# SF32LB55x register map
File version: 1.0
CPU: CM33 r0p1, little endian, MPU, FPU, 3 interrupt priority bits
Registers are 32-bit, read-write, reset 0x0 unless marked. A register's access mark holds for its fields unless they carry their own. Offsets are from the block's base; [hi:lo] are bit positions; {n}, {i} and the like mark numbered series; 'fields as' and 'values as' point back to an identical list.

## PTC1
Base 0x40020000
Same registers: PTC2 0x4005B000
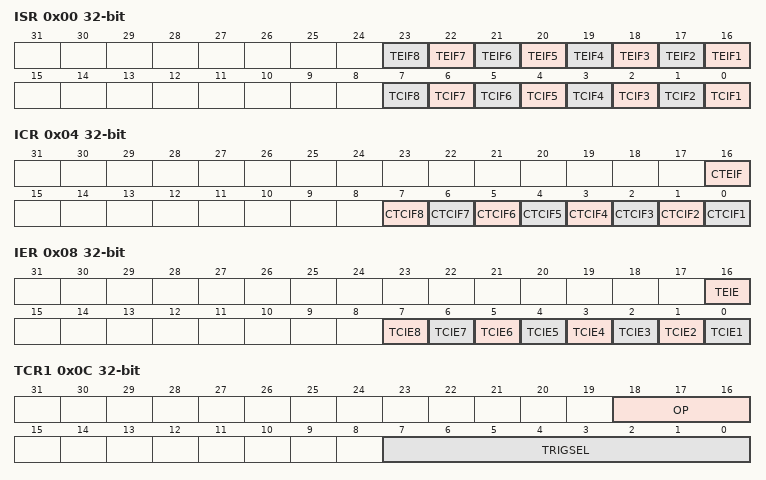
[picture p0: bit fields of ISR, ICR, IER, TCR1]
0x00 ISR — interrupt status register
  [n+15] TEIF{n} (n=1..8) — transfer error flag for task {n}
  [n-1] TCIF{n} (n=1..8) — task complete interrupt flag for task {n}
0x04 ICR — interrupt clear register
  [16] CTEIF — clear transfer error flag
  [n-1] CTCIF{n} (n=1..8) — clear task complete interrupt flag for task {n}
0x08 IER — interrupt enable register
  [16] TEIE — enable transfer error flag
  [n-1] TCIE{n} (n=1..8) — enable task complete interrupt for task {n}
0x0C TCR1 — task 1 control register
  [18:16] OP — task operation 3'b000: direct write data 3'b100: read then XOR with data and write back 3'b101: read then OR with data and write back 3'b110: read then AND with data and write back 3'b111: read then add with data and write back
  [7:0] TRIGSEL — select trigger source 0: task will not be triggered others: task will be triggered by selected source
0x10 TAR1 — task 1 address register
  [31:0] ADDR — peripheral address to access to
0x14 TDR1 — task 1 data register
  [31:0] DATA — data value for task operation
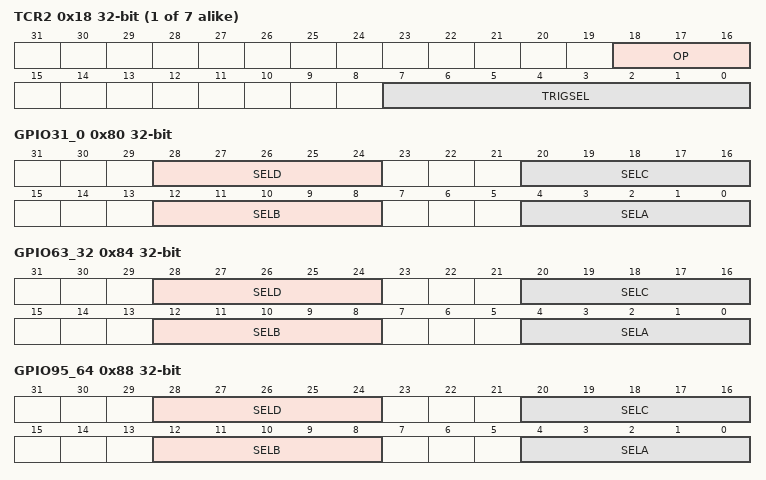
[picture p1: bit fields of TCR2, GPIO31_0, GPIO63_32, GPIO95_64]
{0x0+0xC*i} TCR{i} (i=2..8)
  fields as TCR1
{0x4+0xC*i} TAR{i} (i=2..8)
  [31:0] ADDR — peripheral address to access to
{0x8+0xC*i} TDR{i} (i=2..8)
  [31:0] DATA — data value for task operation
{0x6C+4i} MEM{i} (i=1..4) — temporary memory {i}
  [31:0] DATA — memory to store temporary variables
0x80 GPIO31_0
  [28:24] SELD — select trigger D of GPIO 31~0
  [20:16] SELC — select trigger C of GPIO 31~0
  [12:8] SELB — select trigger B of GPIO 31~0
  [4:0] SELA — select trigger A of GPIO 31~0 0: select GPIO 0 1: select GPIO 1 ...... 31: select GPIO 31
0x84 GPIO63_32
  [28:24] SELD — select trigger D of GPIO 63~32
  [20:16] SELC — select trigger C of GPIO 63~32
  [12:8] SELB — select trigger B of GPIO 63~32
  [4:0] SELA — select trigger A of GPIO 63~32 0: select GPIO 32 1: select GPIO 33 ...... 31: select GPIO 63
0x88 GPIO95_64
  [28:24] SELD — select trigger D of GPIO 95~64
  [20:16] SELC — select trigger C of GPIO 95~64
  [12:8] SELB — select trigger B of GPIO 95~64
  [4:0] SELA — select trigger A of GPIO 95~64 0: select GPIO 64 1: select GPIO 65 ...... 31: select GPIO 95

## HPSYS_AON
Base 0x40030000
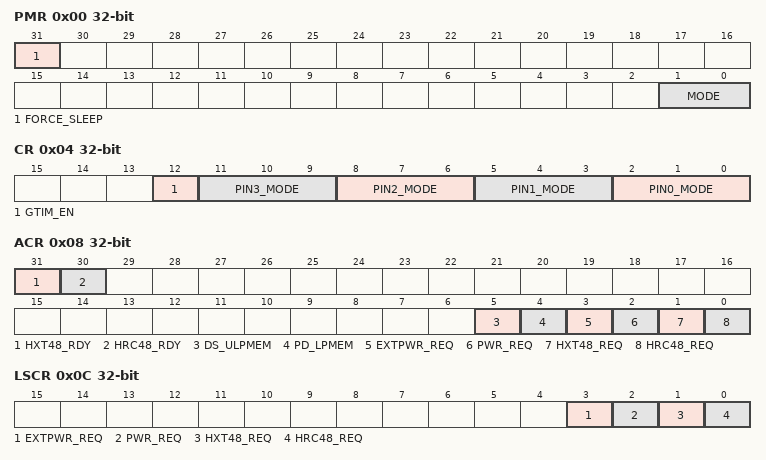
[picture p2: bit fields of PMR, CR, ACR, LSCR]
0x00 PMR — Power Mode Register
  [31] FORCE_SLEEP — force to enter low power mode (for debug only)
  [1:0] MODE — Power Mode: 2'h0 - active/idle; 2'h1 - light sleep; 2'h2 - deep sleep; 2'h3 - standby
0x04 CR — Control Register
  [12] GTIM_EN — Enable global timer
  [11:9] PIN3_MODE — mode for wakeup PIN3 (PA80)
  [8:6] PIN2_MODE — mode for wakeup PIN2 (PA79)
  [5:3] PIN1_MODE — mode for wakeup PIN1 (PA78)
  [2:0] PIN0_MODE — mode for wakeup PIN0 (PA77) 0 - high level, 1 - low level, 2 - pos edge, 3 - neg edge, 4/5/6/7: pos or neg edge
0x08 ACR — Active Mode Control register
  [31] HXT48_RDY — Indicate hxt48 is ready
  [30] HRC48_RDY — Indicate hrc48 is ready
  [5] DS_ULPMEM — for debug only
  [4] PD_LPMEM — for debug only
  [3] EXTPWR_REQ — Request power for LPSYS during Active mode
  [2] PWR_REQ — Request power for HPSYS during Active mode
  [1] HXT48_REQ — Request hxt48 in active mode
  [0] HRC48_REQ — Request hrc48 in active mode
0x0C LSCR — Light Sleep Ctrl Register
  [3] EXTPWR_REQ — Request power for LPSYS during Light Sleep mode
  [2] PWR_REQ — Request power for HPSYS during Light Sleep mode
  [1] HXT48_REQ — Request hxt48 in Light Sleep mode
  [0] HRC48_REQ — Request hrc48 in Light Sleep mode
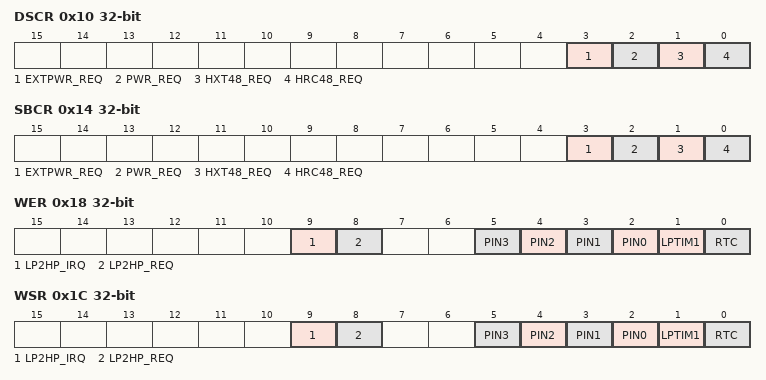
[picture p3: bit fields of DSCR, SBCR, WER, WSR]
0x10 DSCR — Deep Sleep Ctrl Register
  [3] EXTPWR_REQ — Request power for LPSYS during Deep Sleep mode
  [2] PWR_REQ — Request power for HPSYS during Deep Sleep mode
  [1] HXT48_REQ — Request hxt48 in Deep Sleep mode
  [0] HRC48_REQ — Request hrc48 in Deep Sleep mode
0x14 SBCR — Standby Mode Ctrl Register
  [3] EXTPWR_REQ — Request power for LPSYS during Standby mode
  [2] PWR_REQ — Request power for HPSYS during Standby mode
  [1] HXT48_REQ — Request hxt48 in Standby mode
  [0] HRC48_REQ — Request hrc48 in Standby mode
0x18 WER — Wakeup Enable register
  [9] LP2HP_IRQ — Set 1 to enable MAILBOX2 as wakeup source
  [8] LP2HP_REQ — Set 1 to enable LPSYS request as wakeup source
  [n+2] PIN{n} (n=0..3) — Set 1 to enable PA{n+77} as wakeup source
  [1] LPTIM1 — Set 1 to enable LPTIM1 as wakeup source
  [0] RTC — Set 1 to enable RTC as wakeup source
0x1C WSR — Wakeup Status register
  [9] LP2HP_IRQ — Indicates the wakeup status from MAILBOX2. Note: the status is masked by WER
  [8] LP2HP_REQ — Indicates the wakeup status from LPSYS request. Note: the status is masked by WER
  [n+2] PIN{n} (n=0..3) — Indicates the wakeup status from PA{n+77} request. Note: the status is masked by WER
  [1] LPTIM1 — Indicates the wakeup status from LPTIM1. Note: the status is masked by WER
  [0] RTC — Indicates the wakeup status from RTC. Note: the status is masked by WER
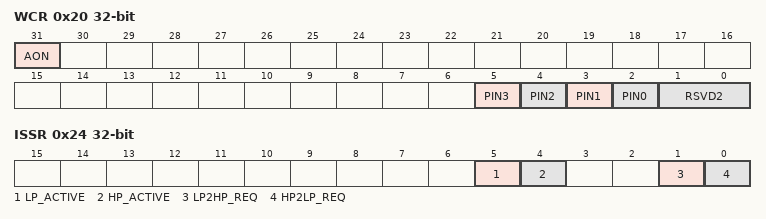
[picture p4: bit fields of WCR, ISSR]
0x20 WCR — Wakeup Clear register
  [31] AON — Write 1 to clear the AON wakeup IRQ status
  [n+2] PIN{n} (n=0..3) — Write 1 to clear the PA{n+77} wakeup source. Only valid if PIN wakeup is configured as edge trigger
  [1:0] RSVD2 — Note: for LPTIM and RTC, clear the wakeup status directly in the orignal module
0x24 ISSR — Inter System Wakeup Register
  [5] LP_ACTIVE — read 1 indicates LPSYS is active
  [4] HP_ACTIVE — write 1 to indicates HPSYS is active
  [1] LP2HP_REQ — indicate LPSYS request exists
  [0] HP2LP_REQ — write 1 to request LPSYS to stay in active mode
0x28 ANACR — Analog Control Register
  [0] PA_ISO — Set 1 to force IO(PA) into retention mode
0x2C GTIMR — Global Timer Register
  [31:0] CNT — Global timer value
0x30 RESERVE0 — Reserved Register 0
  [31:0] DATA — for debug only
0x34 RESERVE1 — Reserved Register 1
  [31:0] DATA — for debug only
